# PY32F030xx register map
Vendor: Puya; Series: PY32F0; File version: 1.0.0
CPU: CM0+ r0p1, little endian, no MPU, no FPU, 4 interrupt priority bits
Registers are 32-bit, read-write, reset 0x0 unless marked. A register's access mark holds for its fields unless they carry their own. Offsets are from the block's base; [hi:lo] are bit positions; {n}, {i} and the like mark numbered series.

## TIM16 — General purpose timer
Base 0x40014400
Same registers: TIM17 0x40014800
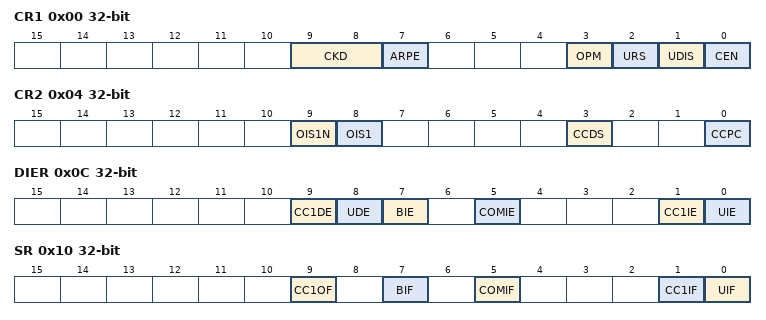
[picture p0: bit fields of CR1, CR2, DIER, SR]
0x00 CR1 — TIM16 control register1
  [9:8] CKD — Prescaler factor
  [7] ARPE — Auto-reload preload enable
    0=Disabled (TIMx_APRR register is not buffered); 1=Enabled (TIMx_APRR register is buffered)
  [3] OPM — One pulse mode
  [2] URS — Update request source
    0=AnyEvent (Any of counter overflow/underflow, setting UG, or update through slave mode, generates an update interrupt or DMA request); 1=CounterOnly (Only counter overflow/underflow generates an update interrupt or DMA request)
  [1] UDIS — Update disable
    0=Enabled (Update event enabled); 1=Disabled (Update event disabled)
  [0] CEN — Counter enable
    0=Disabled (Counter disabled); 1=Enabled (Counter enabled)
0x04 CR2 — control register 2
  [9] OIS1N — Output Idle state 1
  [8] OIS1 — Output Idle state 1
  [3] CCDS — Capture/compare DMA selection
  [0] CCPC — Capture/compare preloaded control
0x0C DIER — DMA/Interrupt enable register
  [9] CC1DE — Compare/capture DMA requeset enable
  [8] UDE — Update DMA request enable
  [7] BIE — Break interrupt enable
  [5] COMIE — Com interrupt enable
  [1] CC1IE — Capture/Compare 1 interrupt enable
  [0] UIE — Update interrupt enable
0x10 SR — status register
  [9] CC1OF — Update interrupt flag
  [7] BIF — Break interrupt flag
  [5] COMIF — Com interrupt flag
  [1] CC1IF — Capture/Compare 1 interrupt flag
  [0] UIF — Update interrupt flag
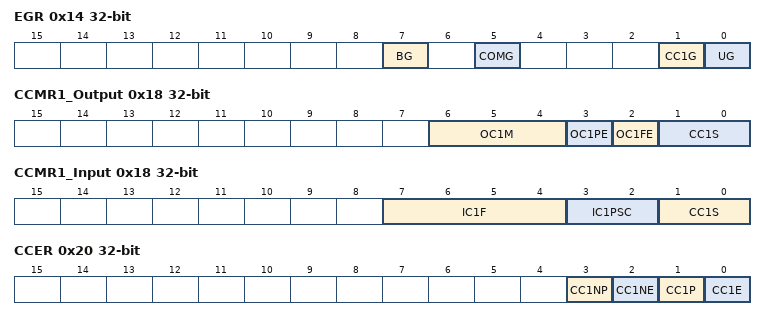
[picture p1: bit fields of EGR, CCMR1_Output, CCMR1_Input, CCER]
0x14 EGR wo — event generation register
  [7] BG — Break event generation
  [5] COMG — COM evnet generation
  [1] CC1G — Capture/Compare 1 generation
    1=Trigger (If CC1 is an output: CC1IF flag is set, Corresponding interrupt or DMA request is sent if enabled. If CC1 is an input: The current value of the counter is captured in TIMx_CCR1 register.)
  [0] UG — Update generation
    1=Trigger (Re-initializes the timer counter and generates an update of the registers.)
0x18 CCMR1_Output — capture/compare mode register (output mode)
  [6:4] OC1M — Output Compare 1 mode
    0=Frozen (The comparison between the output compare register TIMx_CCRy and the counter TIMx_CNT has no effect on the outputs); 1=ActiveOnMatch (Set channel to active level on match. OCyREF signal is forced high when the counter matches the capture/compare register); 2=InactiveOnMatch (Set channel to inactive level on match. OCyREF signal is forced low when the counter matches the capture/compare register); 3=Toggle (OCyREF toggles when TIMx_CNT=TIMx_CCRy); 4=ForceInactive (OCyREF is forced low); 5=ForceActive (OCyREF is forced high); 6=PwmMode1 (In upcounting, channel is active as long as TIMx_CNT<TIMx_CCRy else inactive. In downcounting, channel is inactive as long as TIMx_CNT>TIMx_CCRy else active); 7=PwmMode2 (Inversely to PwmMode1)
  [3] OC1PE — Output Compare 1 preload enable
    0=Disabled (Preload register on CCR1 disabled. New values written to CCR1 are taken into account immediately); 1=Enabled (Preload register on CCR1 enabled. Preload value is loaded into active register on each update event)
  [2] OC1FE — Output Compare 1 fast enable
  [1:0] CC1S — Capture/Compare 1 selection
    0=Output (CC1 channel is configured as output)
0x18 CCMR1_Input (alternate view of CCMR1_Output) — capture/compare mode register 1 (input mode)
  [7:4] IC1F — Input capture 1 filter
    0=No filter, sampling is done at fDTS; 1=FCK_INT_N2 (fSAMPLING=fCK_INT, N=2); 2=FCK_INT_N4 (fSAMPLING=fCK_INT, N=4); 3=FCK_INT_N8 (fSAMPLING=fCK_INT, N=8); 4=FDTS_Div2_N6 (fSAMPLING=fDTS/2, N=6); 5=FDTS_Div2_N8 (fSAMPLING=fDTS/2, N=8); 6=FDTS_Div4_N6 (fSAMPLING=fDTS/4, N=6); 7=FDTS_Div4_N8 (fSAMPLING=fDTS/4, N=8); 8=FDTS_Div8_N6 (fSAMPLING=fDTS/8, N=6); 9=FDTS_Div8_N8 (fSAMPLING=fDTS/8, N=8); 10=FDTS_Div16_N5 (fSAMPLING=fDTS/16, N=5); 11=FDTS_Div16_N6 (fSAMPLING=fDTS/16, N=6); 12=FDTS_Div16_N8 (fSAMPLING=fDTS/16, N=8); 13=FDTS_Div32_N5 (fSAMPLING=fDTS/32, N=5); 14=FDTS_Div32_N6 (fSAMPLING=fDTS/32, N=6); 15=FDTS_Div32_N8 (fSAMPLING=fDTS/32, N=8)
  [3:2] IC1PSC — Input capture 1 prescaler
  [1:0] CC1S — Capture/Compare 1 selection
    1=TI1 (CC1 channel is configured as input, IC1 is mapped on TI1); 2=TI2 (CC1 channel is configured as input, IC1 is mapped on TI2); 3=TRC (CC1 channel is configured as input, IC1 is mapped on TRC)
0x20 CCER — capture/compare enable register
  [3] CC1NP — Capture/Compare 1 output Polarity
  [2] CC1NE — Capture/Compare 1 complementary output enable
  [1] CC1P — Capture/Compare 1 output Polarity
  [0] CC1E — Capture/Compare 1 output enable
0x24 CNT — counter
  [15:0] CNT — counter value
0x28 PSC — prescaler
  [15:0] PSC — Prescaler value
0x2C ARR — auto-reload register
  [15:0] ARR — Auto-reload value
0x30 RCR — repetition counter register
  [7:0] REP — Repetition counter value
{0x30+4i} CCR{i} (i=1..1) — capture/compare register {i}
  [15:0] CCR1 — Capture/Compare 1 value
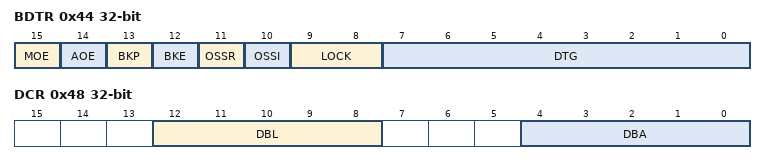
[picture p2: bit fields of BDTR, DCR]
0x44 BDTR — break and dead-time register
  [15] MOE — Main output enable
  [14] AOE — Automatic output enable
  [13] BKP — Break polarity
  [12] BKE — Break enable
  [11] OSSR — Off-state selection for Run mode
  [10] OSSI — Off-state selection for Idle mode
  [9:8] LOCK — Lock configuration
  [7:0] DTG — Dead-time generator setup
0x48 DCR — DMA control register
  [12:8] DBL — DMA burst length
  [4:0] DBA — DMA base address
0x4C DMAR — DMA address for full transfer
  [31:0] DMAB — DMA register for burst accesses
